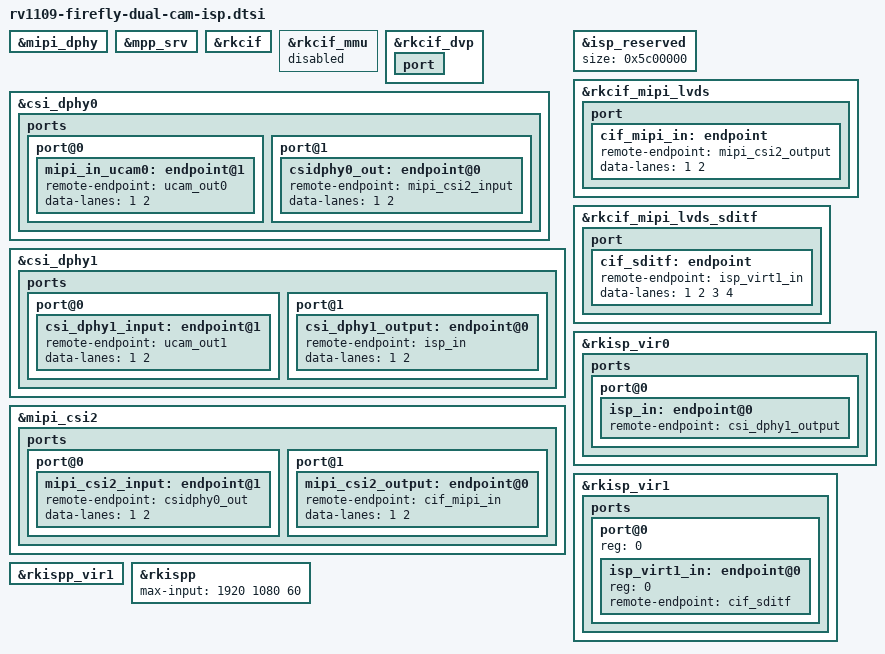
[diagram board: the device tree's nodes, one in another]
&mipi_dphy {
	status = "okay";
};

&mpp_srv {
	status = "okay";
};

&rkcif {
	status = "okay";
};

&rkcif_mmu {
	status = "disabled";
};

&rkcif_dvp {
	status = "okay";

	port {
		/* Parallel bus endpoint */
		/*
		cif_para_in: endpoint {
			remote-endpoint = <&cam_para_out1>;
			bus-width = <12>;
			hsync-active = <1>;
			vsync-active = <0>;
		};
		*/
	};
};

&csi_dphy0 {
	status = "okay";
	ports {
		port@0 {
			mipi_in_ucam0: endpoint@1 {
				remote-endpoint = <&ucam_out0>;
				data-lanes = <1 2>;
			};
		};
		port@1 {
			csidphy0_out: endpoint@0 {
				remote-endpoint = <&mipi_csi2_input>;
				data-lanes = <1 2>;
			};
		};
	};
};

&csi_dphy1 {
	status = "okay";
	ports {
		port@0 {
			csi_dphy1_input: endpoint@1 {
				remote-endpoint = <&ucam_out1>;
				data-lanes = <1 2>;
			};
		};
		port@1 {
			csi_dphy1_output: endpoint@0 {
				remote-endpoint = <&isp_in>;
				data-lanes = <1 2>;
			};
		};
	};
};

/* isp cma buffer don't fiddle with it, dual camera(1920 * 1080) need 92M buffer */
&isp_reserved {
	size = <0x5c00000>;
};

&mipi_csi2 {
	status = "okay";
	ports {
		port@0 {
			mipi_csi2_input: endpoint@1 {
				remote-endpoint = <&csidphy0_out>;
				data-lanes = <1 2>;
			};
		};

		port@1 {
			mipi_csi2_output: endpoint@0 {
				remote-endpoint = <&cif_mipi_in>;
				data-lanes = <1 2>;
			};
		};
	};
};

&rkcif_mipi_lvds {
	status = "okay";
	port {
		cif_mipi_in: endpoint {
			remote-endpoint = <&mipi_csi2_output>;
			data-lanes = <1 2>;
		};
	};
};

&rkcif_mipi_lvds_sditf {
	status = "okay";

	port {
		cif_sditf: endpoint {
			remote-endpoint = <&isp_virt1_in>;
			data-lanes = <1 2 3 4>;
		};
	};
};

&rkisp_vir0 {
	ports {
		port@0 {
			isp_in: endpoint@0 {
				remote-endpoint = <&csi_dphy1_output>;
			};
		};
	};
};

&rkisp_vir1 {
	status = "okay";
	ports {
		port@0 {
			reg = <0>;
			#address-cells = <1>;
			#size-cells = <0>;

			isp_virt1_in: endpoint@0 {
				reg = <0>;
				remote-endpoint = <&cif_sditf>;
			};
		};
	};
};

&rkispp_vir1 {
	status = "okay";
};

&rkispp {
	status = "okay";
	/* the max input w h and fps of mulit sensor */
	max-input = <1920 1080 60>;
};
